# f29h85x_rtdma_ch_regs register map
Vendor: Texas Instruments
Peripheral module from a debugger description file (folder C29).
Registers are 32-bit, read-write, no defined reset value unless marked. A register's access mark holds for its fields unless they carry their own. Offsets are as the file gives them; lines under a group give offsets from that group; [hi:lo] are bit positions; {n}, {i} and the like mark numbered series; 'fields as' and 'values as' point back to an identical list; <NAME> marks a mode.

## RTDMA_CH_REGS — RTDMA CH Registers
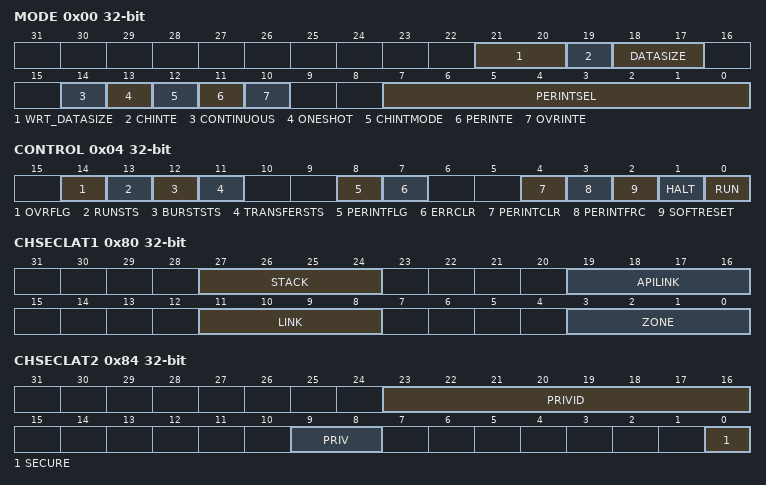
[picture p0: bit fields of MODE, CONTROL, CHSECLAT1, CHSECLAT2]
0x00 MODE
  [21:20] WRT_DATASIZE — Write Data Size Mode Bit
  [19] CHINTE — Channel Interrupt Enable Bit
  [18:17] DATASIZE — Data Size Mode Bit
  [14] CONTINUOUS — Continuous Mode Bit
  [13] ONESHOT — One Shot Mode Bit
  [12] CHINTMODE — Channel Interrupt Mode
  [11] PERINTE — Peripheral Interrupt Enable
  [10] OVRINTE — Overflow Interrupt Enable
  [7:0] PERINTSEL — Peripheral Interrupt and Sync Select
0x04 CONTROL access per field
  [14] OVRFLG ro — Overflow Flag Bit
  [13] RUNSTS ro — Run Status Bit
  [12] BURSTSTS ro — Burst Status Bit
  [11] TRANSFERSTS ro — Transfer Status Bit
  [8] PERINTFLG ro — Interrupt Flag Bit
  [7] ERRCLR rw — Error Clear Bit
  [4] PERINTCLR rw — Interrupt Clear Bit
  [3] PERINTFRC rw — Interrupt Force Bit
  [2] SOFTRESET rw — Soft Reset Bit
  [1] HALT rw — Halt Bit
  [0] RUN rw — Run Bit
0x08 BURST_SIZE
  [7:0] BURSTSIZE — Burst Transfer Size
0x0C BURST_COUNT ro
  [7:0] BURSTCOUNT — Burst Transfer Size
0x10 SRC_BURST_STEP — Source Burst Step Register
  [15:0] SRCBURSTSTEP — Source post-increment/decrement step size of a burst
0x14 DST_BURST_STEP — Destination Burst Step Register
  [15:0] DSTBURSTSTEP — Destination post-increment/decrement step size of a burst
0x18 TRANSFER_SIZE
  [15:0] TRANSFERSIZE — These bits specify the number of bursts to transfer:
0x1C TRANSFER_COUNT ro
  [15:0] TRANSFERCOUNT — These bits specify the current transfer counter value:
0x20 SRC_TRANSFER_STEP — Source Transfer Step Register
  [15:0] SRCTRANSFERSTEP — Source post-increment/decrement step size of a transfer
0x24 DST_TRANSFER_STEP — Destination Transfer Step Register
  [15:0] DSTTRANSFERSTEP — Destination post-increment/decrement step size of a transfer
0x28 SRC_WRAP_SIZE — Source Wrap Size Register
  [15:0] WRAPSIZE — Number of bursts to transfer before wrapping
0x2C SRC_WRAP_COUNT ro — Source Wrap Count Register
  [15:0] WRAPSIZE — These bits indicate the current wrap counter value:
0x30 SRC_WRAP_STEP — Source Wrap Step Register
  [15:0] WRAPSTEP — Source post-increment/decrement step size for a wrap
0x34 DST_WRAP_SIZE — Destination Wrap Size Register
  [15:0] WRAPSIZE — Number of bursts to transfer before wrapping
0x38 DST_WRAP_COUNT ro — Destination Wrap Count Register
  fields as SRC_WRAP_COUNT
0x3C DST_WRAP_STEP — Destination Wrap Step Register
  [15:0] WRAPSTEP — Destination post-increment/decrement step size for a wrap
0x40 SRC_BEG_ADDR_SHADOW — Source Begin Address Shadow Register
  [31:0] BEGADDR — 32-bit address value
0x44 SRC_ADDR_SHADOW — Source Address Shadow Register
  [31:0] ADDR — 32-bit address value
0x48 SRC_BEG_ADDR_ACTIVE ro — Source Begin Address Active Register
  [31:0] BEGADDR — 32-bit address value
0x4C SRC_ADDR_ACTIVE ro — Source Address Active Register
  [31:0] ADDR — 32-bit address value
0x50 DST_BEG_ADDR_SHADOW — Destination Begin Address Shadow Register
  [31:0] BEGADDR — 32-bit address value
0x54 DST_ADDR_SHADOW — Destination Address Shadow Register
  [31:0] ADDR — 32-bit address value
0x58 DST_BEG_ADDR_ACTIVE ro — Destination Begin Address Active Register
  [31:0] BEGADDR — 32-bit address value
0x5C DST_ADDR_ACTIVE ro — Destination Address Active Register
  [31:0] ADDR — 32-bit address value
0x80 CHSECLAT1 ro — Channel Security Details Latch Register
  [27:24] STACK — Channel owner Stack
  [19:16] APILINK — Channel owner Clink
  [11:8] LINK — Channel owner Link
  [3:0] ZONE — Channel owner zone
0x84 CHSECLAT2 ro — Channel Security Details Latch Register
  [23:16] PRIVID — Channel PRIVID information
  [9:8] PRIV — Channel PRIV information
  [0] SECURE — Channel SECURE Information
0xA0 BURST_INTF_CTRL — Burst Interface Control Register
  [1:0] BURSTCTRL — Control Burst Interface operation
0x100 CHCFG_LOCK — Channel Configuration Temporary Lock
  [0] LOCK — Temporary Lock
0x104 CHCFG_COMMIT — Channel Configuration Permanent Commit
  [0] COMMIT — Permanent Commit
